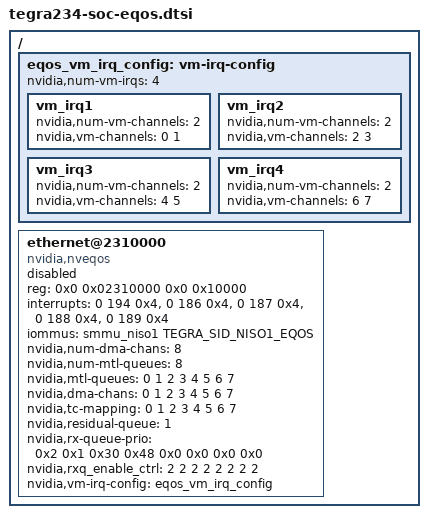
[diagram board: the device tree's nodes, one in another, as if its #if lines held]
/*
 * Copyright (c) 2020-2021, NVIDIA CORPORATION.  All rights reserved.
 *
 * This program is free software; you can redistribute it and/or modify it
 * under the terms and conditions of the GNU General Public License,
 * version 2, as published by the Free Software Foundation.
 *
 * This program is distributed in the hope it will be useful, but WITHOUT
 * ANY WARRANTY; without even the implied warranty of MERCHANTABILITY or
 * FITNESS FOR A PARTICULAR PURPOSE.  See the GNU General Public License for
 * more details.
 *
 * You should have received a copy of the GNU General Public License
 * along with this program.  If not, see <http://www.gnu.org/licenses/>.
 */

/*
 * tegra194-soc-eqos.dtsi: Ethernet QOS DTSI file.
 */

/ {
	eqos_vm_irq_config: vm-irq-config {
		nvidia,num-vm-irqs = <4>;
		vm_irq1 {
			nvidia,num-vm-channels = <2>;
			nvidia,vm-channels = <0 1>;
		};
		vm_irq2 {
			nvidia,num-vm-channels = <2>;
			nvidia,vm-channels = <2 3>;
		};
		vm_irq3 {
			nvidia,num-vm-channels = <2>;
			nvidia,vm-channels = <4 5>;
		};
		vm_irq4 {
			nvidia,num-vm-channels = <2>;
			nvidia,vm-channels = <6 7>;
		};
	};

	ethernet@2310000 {
		compatible = "nvidia,nveqos";
		reg = <0x0 0x02310000 0x0 0x10000>;    /* EQOS Base Register */
		reg-names = "mac-base";
		interrupts = <0 194 0x4>,       /* common */
			     <0 186 0x4>, /* vm0 */
			     <0 187 0x4>, /* vm1 */
			     <0 188 0x4>, /* vm2 */
			     <0 189 0x4>; /* vm3 */
#if TEGRA_IOMMU_DT_VERSION >= DT_VERSION_2
		iommus = <&smmu_niso1 TEGRA_SID_NISO1_EQOS>;
#else
		iommus = <&smmu TEGRA_SID_EQOS>;
#endif
		nvidia,num-dma-chans = <8>;
		nvidia,num-mtl-queues = <8>;
		nvidia,mtl-queues = <0 1 2 3 4 5 6 7>;
		nvidia,dma-chans = <0 1 2 3 4 5 6 7>;
		nvidia,tc-mapping = <0 1 2 3 4 5 6 7>;
		/* Residual Queue can be any valid queue except RxQ0 */
		nvidia,residual-queue = <1>;
		nvidia,rx-queue-prio = <0x2 0x1 0x30 0x48 0x0 0x0 0x0 0x0>;
		nvidia,rxq_enable_ctrl = <2 2 2 2 2 2 2 2>;
		nvidia,vm-irq-config = <&eqos_vm_irq_config>;
		status = "disabled";
	};
};
